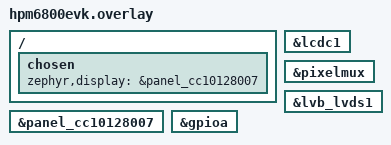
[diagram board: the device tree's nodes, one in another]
/*
* Copyright 2024-2026 HPMicro
* SPDX-License-Identifier: Apache-2.0
*/

/ {
	chosen {
		zephyr,display = &panel_cc10128007;
	};
};

&lcdc1 {
	status = "okay";
};

&pixelmux {
	status = "okay";
};

&lvb_lvds1 {
	status = "okay";
};

&panel_cc10128007 {
	status = "okay";
};

/*
* backlight control
*/
&gpioa {
	status = "okay";
};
